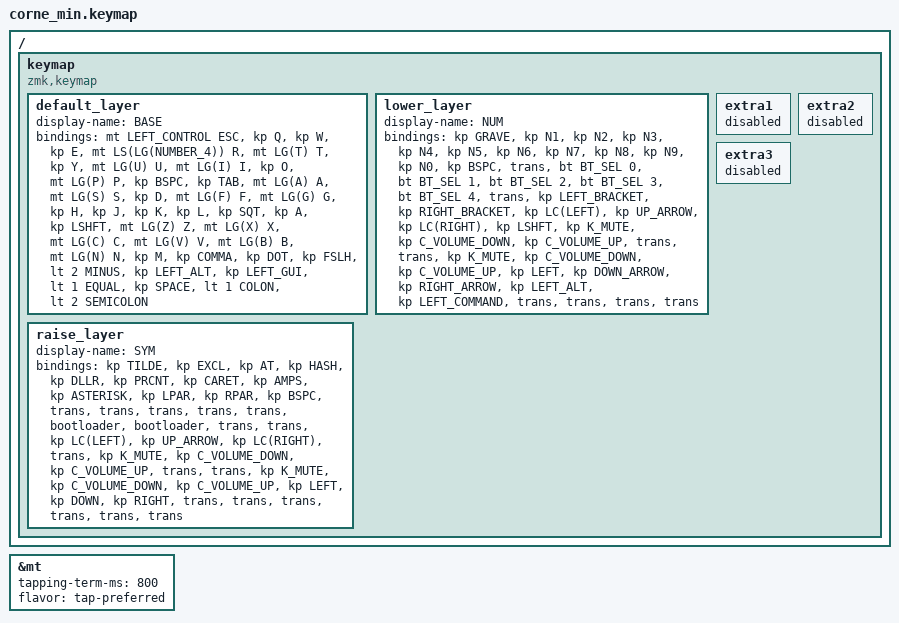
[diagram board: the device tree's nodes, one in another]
#include <behaviors.dtsi>
#include <dt-bindings/zmk/bt.h>
#include <dt-bindings/zmk/keys.h>

&mt {
    tapping-term-ms = <800>;
    flavor = "tap-preferred";
};

/ {
    keymap {
        compatible = "zmk,keymap";

        default_layer {
            display-name = "BASE";
            bindings = <
&mt LEFT_CONTROL ESC  &kp Q  &kp W  &kp E  &mt LS(LG(NUMBER_4)) R  &mt LG(T) T  &kp Y  &mt LG(U) U  &mt LG(I) I  &kp O  &mt LG(P) P  &kp BSPC  &kp TAB  &mt LG(A) A  &mt LG(S) S  &kp D  &mt LG(F) F  &mt LG(G) G  &kp H  &kp J  &kp K  &kp L  &kp SQT  &kp A  &kp LSHFT  &mt LG(Z) Z  &mt LG(X) X  &mt LG(C) C  &mt LG(V) V  &mt LG(B) B  &mt LG(N) N  &kp M  &kp COMMA  &kp DOT  &kp FSLH  &lt 2 MINUS  &kp LEFT_ALT  &kp LEFT_GUI  &lt 1 EQUAL  &kp SPACE  &lt 1 COLON  &lt 2 SEMICOLON
            >;
        };

        lower_layer {
            display-name = "NUM";
            bindings = <
&kp GRAVE  &kp N1  &kp N2  &kp N3  &kp N4  &kp N5  &kp N6  &kp N7  &kp N8  &kp N9  &kp N0  &kp BSPC  &trans  &bt BT_SEL 0  &bt BT_SEL 1  &bt BT_SEL 2  &bt BT_SEL 3  &bt BT_SEL 4  &trans  &kp LEFT_BRACKET  &kp RIGHT_BRACKET  &kp LC(LEFT)  &kp UP_ARROW  &kp LC(RIGHT)  &kp LSHFT  &kp K_MUTE  &kp C_VOLUME_DOWN  &kp C_VOLUME_UP  &trans  &trans  &kp K_MUTE  &kp C_VOLUME_DOWN  &kp C_VOLUME_UP  &kp LEFT  &kp DOWN_ARROW  &kp RIGHT_ARROW  &kp LEFT_ALT  &kp LEFT_COMMAND  &trans  &trans  &trans  &trans
            >;
        };

        raise_layer {
            display-name = "SYM";
            bindings = <
&kp TILDE  &kp EXCL  &kp AT  &kp HASH  &kp DLLR  &kp PRCNT  &kp CARET  &kp AMPS  &kp ASTERISK  &kp LPAR  &kp RPAR  &kp BSPC  &trans  &trans  &trans  &trans  &trans  &bootloader  &bootloader  &trans  &trans  &kp LC(LEFT)  &kp UP_ARROW  &kp LC(RIGHT)  &trans  &kp K_MUTE  &kp C_VOLUME_DOWN  &kp C_VOLUME_UP  &trans  &trans  &kp K_MUTE  &kp C_VOLUME_DOWN  &kp C_VOLUME_UP  &kp LEFT  &kp DOWN  &kp RIGHT  &trans  &trans  &trans  &trans  &trans  &trans
            >;
        };

        extra1 { status = "reserved"; };

        extra2 { status = "reserved"; };

        extra3 { status = "reserved"; };
    };
};
